AUTOSAR XML (schema 00050)
standard types defined: Boolean
package /ARRoot
  trigger-interface:
    trigger PowerDoorLockLeftTrigger
    trigger PowerDoorLockRightTrigger
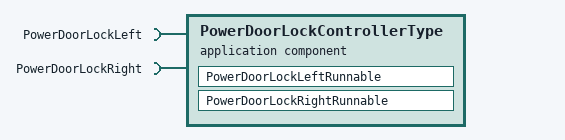
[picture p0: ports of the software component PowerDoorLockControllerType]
  application sw component type PowerDoorLockControllerType
    require port PowerDoorLockLeft
    require port PowerDoorLockRight
    behavior PowerDoorSystemIB
      runnable PowerDoorLockLeftRunnable: synchronous-server-call-point=PowerDoorLockLeft.
      runnable PowerDoorLockRightRunnable: synchronous-server-call-point=PowerDoorLockRight.
  swc implementation PowerDoorLockImpFile: programming-language=C, behavior=PowerDoorSystemIB
  client server interface PowerDoorLockLeftCSIF: client-server-operation=arguments=argument-data-prototype={type=Boolean, direction=OUT}
  client server interface PowerDoorLockRightCSIF: client-server-operation=arguments=argument-data-prototype={type=Boolean, direction=OUT}
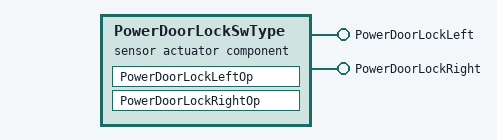
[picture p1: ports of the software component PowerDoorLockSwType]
  sensor actuator sw component type PowerDoorLockSwType
    provide port PowerDoorLockLeft
    provide port PowerDoorLockRight
    behavior PowerDoorLockIB
      runnable PowerDoorLockLeftOp: external-triggering-point=PowerDoorLockLeft.PowerDoorLockLeftTrigger
      runnable PowerDoorLockRightOp: external-triggering-point=PowerDoorLockRight.PowerDoorLockRightTrigger
